VERSION ""

NS_ :

BS_:

BU_: Inverter SensorHub ECU AVA BMS

VAL_TABLE_ InverterCommandMode 0 "CAN Mode" 1 "VSM Mode" ;
VAL_TABLE_ InverterActiveDischargeState 0 "Discharge Disabled" 1 "Discharge Enabled, waiting" 2 "Performing Speed Check" 3 "Discharge Actively occurring" 4 "Discharge Completed" ;
VAL_TABLE_ SelfSensingAssistEnable 0 "Disabled" 1 "Enabled" ;
VAL_TABLE_ InverterRunMode 0 "Torque Mode" 1 "Speed Mode" ;
VAL_TABLE_ RelayState 0 "Relay 1 Status" 1 "Relay 2 Status" 2 "Relay 3 Status" 3 "Relay 4 Status" 4 "Relay 5 Status" 5 "Relay 6 Status" ;
VAL_TABLE_ InverterState 0 "Power On" 1 "Stop" 2 "Open Loop" 3 "Closed Loop" 4 "Wait" 5 "Internal" 6 "Internal" 7 "Internal" 8 "Idle Run" 9 "Idle Stop" 10 "Internal" 11 "Internal" 12 "Internal" ;
VAL_TABLE_ VSMState 0 "VSM Start" 1 "Pre-charge Init" 2 "Pre-charge Active" 3 "Pre-charge Complete" 4 "VSM Wait" 5 "VSM Ready" 6 "Motor Running" 7 "Blink Fault Code" 14 "Shutdown in Process" 15 "Recycle Power" ;
VAL_TABLE_ Write_Success 0 "Not Written" 1 "Success" ;
VAL_TABLE_ Read_Write 0 "Read" 1 "Write" ;

BO_ 288 GPSPos: 8 AVA
 SG_ longitude : 0|32@1- (1,0) [-180|180] "deg" Vector__XXX
 SG_ latitude : 32|32@1- (1,0) [-90|90] "deg" Vector__XXX

BO_ 289 GPSPosAuxiliary: 8 AVA
 SG_ GPSHorizAccuracy : 0|32@1- (1,0) [-3.4028234663852886e+38|3.4028234663852886e+38] "m" Vector__XXX
 SG_ GPSElevation : 32|32@1- (1,0) [-3.4028234663852886e+38|3.4028234663852886e+38] "m" Vector__XXX

BO_ 290 GPSSpeedDirection: 8 AVA
 SG_ GPSGroundSpeed : 0|32@1- (1,0) [-3.4028234663852886e+38|3.4028234663852886e+38] "m/s" Vector__XXX
 SG_ GPSHeading : 32|32@1- (1,0) [-3.4028234663852886e+38|3.4028234663852886e+38] "deg" Vector__XXX

BO_ 291 GPSStatus: 8 AVA
 SG_ GPSRTKStatus : 0|8@1+ (1,0) [0|255] "" Vector__XXX
 SG_ GPSNumSatellites : 8|8@1+ (1,0) [0|255] "" Vector__XXX

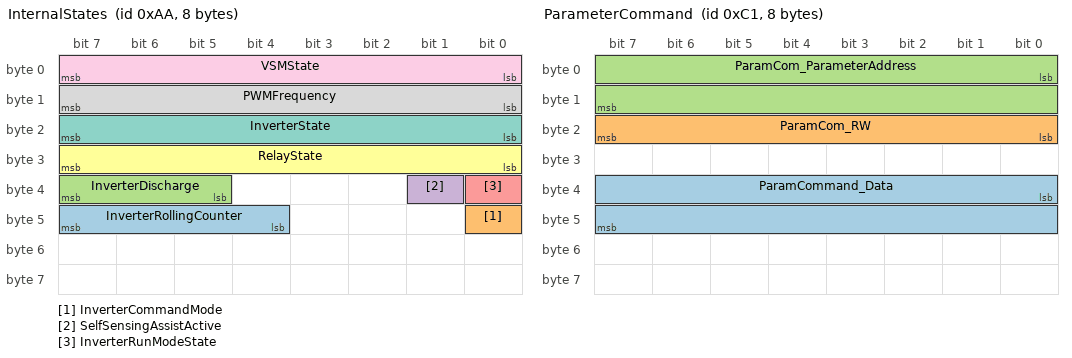
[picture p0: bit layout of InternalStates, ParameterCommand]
BO_ 170 InternalStates: 8 Inverter
 SG_ InverterRollingCounter : 44|4@1+ (1,0) [0|15] "" Vector__XXX
 SG_ InverterCommandMode : 40|1@1+ (1,0) [0|1] "" Vector__XXX
 SG_ InverterDischarge : 37|3@1+ (1,0) [0|4] "" Vector__XXX
 SG_ SelfSensingAssistActive : 33|1@1+ (1,0) [0|1] "" Vector__XXX
 SG_ InverterRunModeState : 32|1@1+ (1,0) [0|1] "" Vector__XXX
 SG_ RelayState : 24|8@1+ (1,0) [0|255] "" Vector__XXX
 SG_ InverterState : 16|8@1+ (1,0) [0|255] "" Vector__XXX
 SG_ PWMFrequency : 8|8@1+ (1,0) [0|255] "kHz" Vector__XXX
 SG_ VSMState : 0|8@1+ (1,0) [0|255] "" Vector__XXX

BO_ 193 ParameterCommand: 8 Inverter
 SG_ ParamCommand_Data : 32|16@1+ (1,0) [0|65535] "" Vector__XXX
 SG_ ParamCom_RW : 16|8@1- (1,0) [0|1] "" Vector__XXX
 SG_ ParamCom_ParameterAddress : 0|16@1+ (1,0) [0|65535] "" Vector__XXX

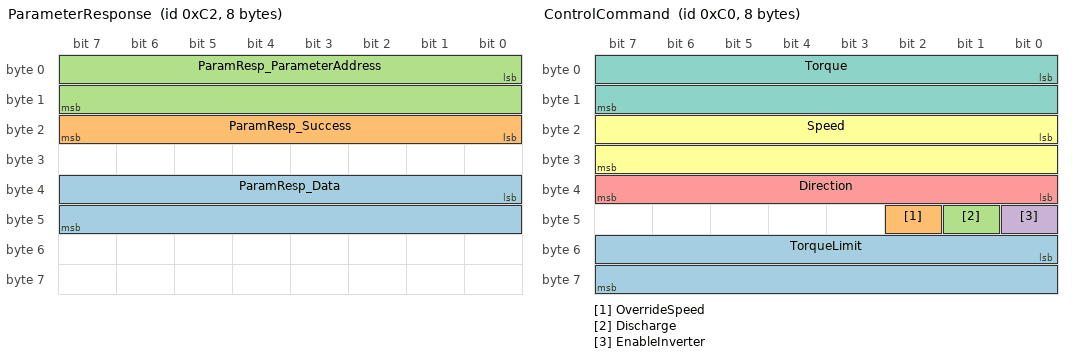
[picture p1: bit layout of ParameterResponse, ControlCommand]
BO_ 194 ParameterResponse: 8 Inverter
 SG_ ParamResp_Data : 32|16@1+ (1,0) [0|65535] "" Vector__XXX
 SG_ ParamResp_Success : 16|8@1+ (1,0) [0|1] "" Vector__XXX
 SG_ ParamResp_ParameterAddress : 0|16@1+ (1,0) [0|65535] "" Vector__XXX

BO_ 192 ControlCommand: 8 Inverter
 SG_ TorqueLimit : 48|16@1- (1,0) [-32768|32767] "0.1Nm" Vector__XXX
 SG_ OverrideSpeed : 42|1@1+ (1,0) [0|1] "" Vector__XXX
 SG_ Discharge : 41|1@1+ (1,0) [0|1] "" Vector__XXX
 SG_ EnableInverter : 40|1@1+ (1,0) [0|1] "" Vector__XXX
 SG_ Direction : 32|8@1+ (1,0) [0|1] "" Vector__XXX
 SG_ Speed : 16|16@1- (1,0) [-32768|32767] "RPM" Vector__XXX
 SG_ Torque : 0|16@1- (1,0) [-32768|32767] "0.1Nm" Vector__XXX

BO_ 177 TorqueCapability: 8 Inverter
 SG_ TorqueCapability : 0|16@1- (1,0) [-32768|32767] "0.1Nm" Vector__XXX

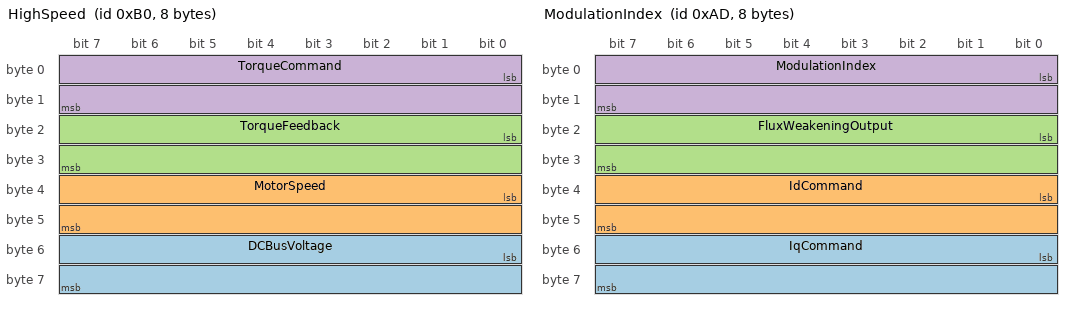
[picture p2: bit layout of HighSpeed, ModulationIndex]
BO_ 176 HighSpeed: 8 Inverter
 SG_ DCBusVoltage : 48|16@1- (0.1,0) [-3276.8|3276.7] "V" Vector__XXX
 SG_ MotorSpeed : 32|16@1- (1,0) [-32768|32767] "RPM" Vector__XXX
 SG_ TorqueFeedback : 16|16@1- (0.1,0) [-3276.8|3276.7] "Nm" Vector__XXX
 SG_ TorqueCommand : 0|16@1- (0.1,0) [-3276.8|3276.7] "Nm" Vector__XXX

BO_ 173 ModulationIndex: 8 Inverter
 SG_ IqCommand : 48|16@1- (1,0) [-32768|32767] "0.1V" Vector__XXX
 SG_ IdCommand : 32|16@1- (1,0) [-32768|32767] "0.1V" Vector__XXX
 SG_ FluxWeakeningOutput : 16|16@1- (1,0) [-32768|32767] "0.1V" Vector__XXX
 SG_ ModulationIndex : 0|16@1- (1,0) [-32768|32767] "0.01x" Vector__XXX

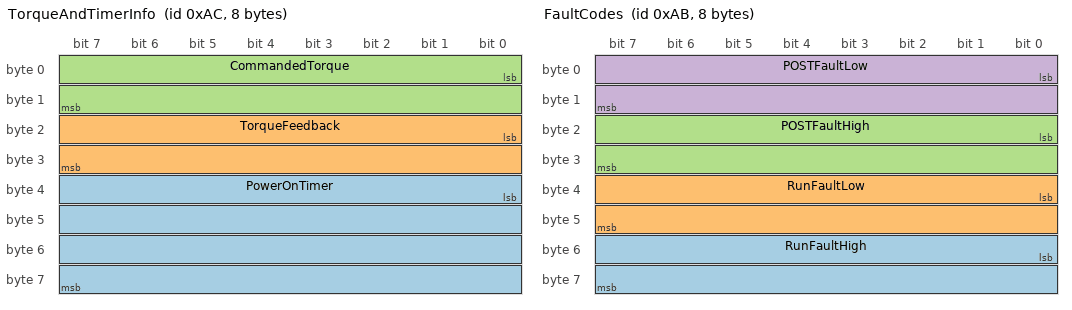
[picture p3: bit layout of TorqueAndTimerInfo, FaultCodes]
BO_ 172 TorqueAndTimerInfo: 8 Inverter
 SG_ PowerOnTimer : 32|32@1+ (1,0) [0|4294967295] "3ms" Vector__XXX
 SG_ TorqueFeedback : 16|16@1- (0.1,0) [-3276.8|3276.7] "Nm" Vector__XXX
 SG_ CommandedTorque : 0|16@1- (1,0) [-32768|32767] "0.1Nm" Vector__XXX

BO_ 171 FaultCodes: 8 Inverter
 SG_ RunFaultHigh : 48|16@1+ (1,0) [0|65535] "" Vector__XXX
 SG_ RunFaultLow : 32|16@1+ (1,0) [0|65535] "" Vector__XXX
 SG_ POSTFaultHigh : 16|16@1+ (1,0) [0|65535] "" Vector__XXX
 SG_ POSTFaultLow : 0|16@1+ (1,0) [0|65535] "" Vector__XXX

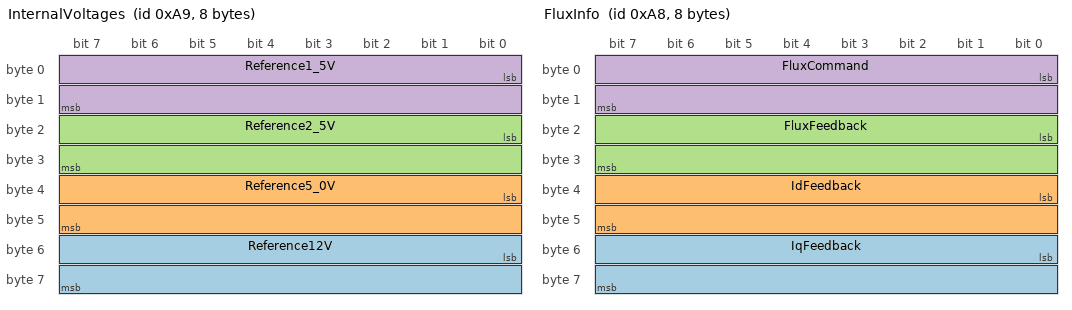
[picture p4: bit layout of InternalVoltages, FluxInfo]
BO_ 169 InternalVoltages: 8 Inverter
 SG_ Reference12V : 48|16@1- (0.01,0) [-327.68|327.67] "V" Vector__XXX
 SG_ Reference5_0V : 32|16@1- (1,0) [-32768|32767] "0.01V" Vector__XXX
 SG_ Reference2_5V : 16|16@1- (1,0) [-32768|32767] "0.01V" Vector__XXX
 SG_ Reference1_5V : 0|16@1- (1,0) [-32768|32767] "0.01V" Vector__XXX

BO_ 168 FluxInfo: 8 Inverter
 SG_ IqFeedback : 48|16@1- (1,0) [-32768|32767] "0.1A" Vector__XXX
 SG_ IdFeedback : 32|16@1- (1,0) [-32768|32767] "0.1A" Vector__XXX
 SG_ FluxFeedback : 16|16@1- (1,0) [-32768|32767] "mWb" Vector__XXX
 SG_ FluxCommand : 0|16@1- (1,0) [-32768|32767] "mWb" Vector__XXX

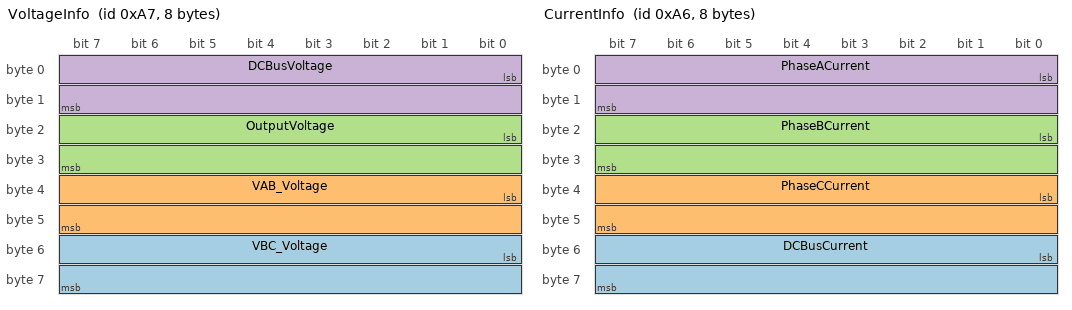
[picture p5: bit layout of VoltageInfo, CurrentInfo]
BO_ 167 VoltageInfo: 8 Inverter
 SG_ VBC_Voltage : 48|16@1- (1,0) [-32768|32767] "0.1V" Vector__XXX
 SG_ VAB_Voltage : 32|16@1- (1,0) [-32768|32767] "0.1V" Vector__XXX
 SG_ OutputVoltage : 16|16@1- (1,0) [-32768|32767] "0.1V" Vector__XXX
 SG_ DCBusVoltage : 0|16@1- (0.1,0) [-3276.8|3276.7] "V" Vector__XXX

BO_ 166 CurrentInfo: 8 Inverter
 SG_ DCBusCurrent : 48|16@1- (0.1,0) [-3276.8|3276.7] "A" Vector__XXX
 SG_ PhaseCCurrent : 32|16@1- (0.1,0) [-3276.8|3276.7] "A" Vector__XXX
 SG_ PhaseBCurrent : 16|16@1- (1,0) [-32768|32767] "0.1A" Vector__XXX
 SG_ PhaseACurrent : 0|16@1- (1,0) [-32768|32767] "0.1A" Vector__XXX

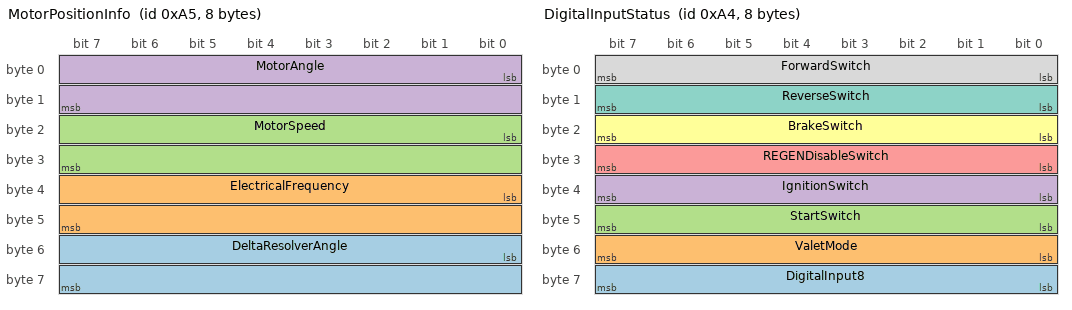
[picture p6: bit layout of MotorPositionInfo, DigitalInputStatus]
BO_ 165 MotorPositionInfo: 8 Inverter
 SG_ DeltaResolverAngle : 48|16@1- (1,0) [-32768|32767] "0.1deg" Vector__XXX
 SG_ ElectricalFrequency : 32|16@1- (1,0) [-32768|32767] "0.1Hz" Vector__XXX
 SG_ MotorSpeed : 16|16@1- (1,0) [-32768|32767] "RPM" Vector__XXX
 SG_ MotorAngle : 0|16@1- (1,0) [-32768|32767] "0.1deg" Vector__XXX

BO_ 164 DigitalInputStatus: 8 Inverter
 SG_ DigitalInput8 : 56|8@1+ (1,0) [0|1] "" Vector__XXX
 SG_ ValetMode : 48|8@1+ (1,0) [0|1] "" Vector__XXX
 SG_ StartSwitch : 40|8@1+ (1,0) [0|1] "" Vector__XXX
 SG_ IgnitionSwitch : 32|8@1+ (1,0) [0|1] "" Vector__XXX
 SG_ REGENDisableSwitch : 24|8@1+ (1,0) [0|1] "" Vector__XXX
 SG_ BrakeSwitch : 16|8@1+ (1,0) [0|1] "" Vector__XXX
 SG_ ReverseSwitch : 8|8@1+ (1,0) [0|1] "" Vector__XXX
 SG_ ForwardSwitch : 0|8@1+ (1,0) [0|1] "" Vector__XXX

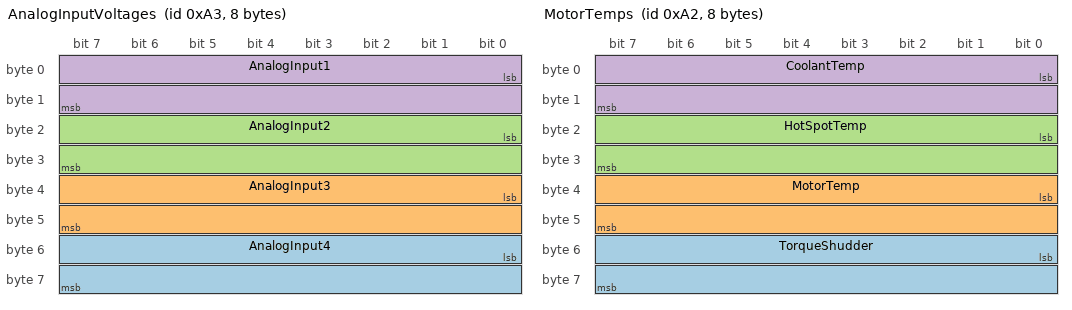
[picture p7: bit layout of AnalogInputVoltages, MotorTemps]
BO_ 163 AnalogInputVoltages: 8 Inverter
 SG_ AnalogInput4 : 48|16@1- (1,0) [-32768|32767] "" Vector__XXX
 SG_ AnalogInput3 : 32|16@1- (1,0) [-32768|32767] "" Vector__XXX
 SG_ AnalogInput2 : 16|16@1- (1,0) [-32768|32767] "" Vector__XXX
 SG_ AnalogInput1 : 0|16@1- (1,0) [-32768|32767] "" Vector__XXX

BO_ 162 MotorTemps: 8 Inverter
 SG_ TorqueShudder : 48|16@1- (1,0) [-32768|32767] "" Vector__XXX
 SG_ MotorTemp : 32|16@1- (1,0) [-32768|32767] "" Vector__XXX
 SG_ HotSpotTemp : 16|16@1- (1,0) [-32768|32767] "" Vector__XXX
 SG_ CoolantTemp : 0|16@1- (1,0) [-32768|32767] "" Vector__XXX

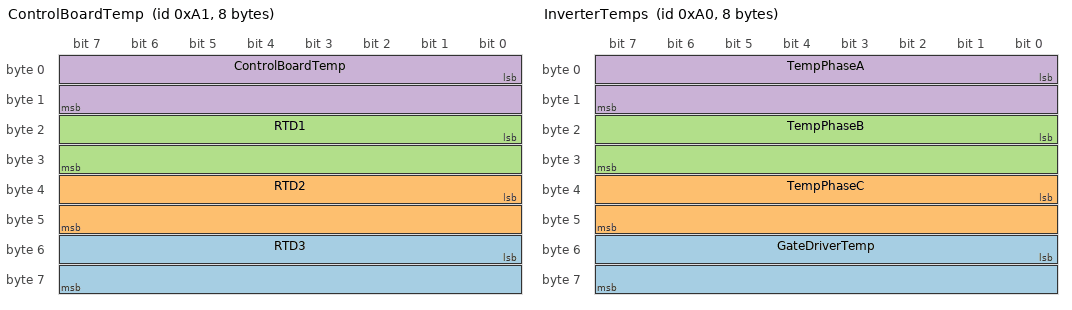
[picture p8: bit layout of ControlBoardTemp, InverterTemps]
BO_ 161 ControlBoardTemp: 8 Inverter
 SG_ RTD3 : 48|16@1- (1,0) [-32768|32767] "" Vector__XXX
 SG_ RTD2 : 32|16@1- (1,0) [-32768|32767] "" Vector__XXX
 SG_ RTD1 : 16|16@1- (1,0) [-32768|32767] "" Vector__XXX
 SG_ ControlBoardTemp : 0|16@1- (1,0) [-32768|32767] "" Vector__XXX

BO_ 160 InverterTemps: 8 Inverter
 SG_ GateDriverTemp : 48|16@1- (1,0) [-32768|32767] "" Vector__XXX
 SG_ TempPhaseC : 32|16@1- (1,0) [-32768|32767] "" Vector__XXX
 SG_ TempPhaseB : 16|16@1- (1,0) [-32768|32767] "" Vector__XXX
 SG_ TempPhaseA : 0|16@1- (1,0) [-32768|32767] "" Vector__XXX

BO_ 0 StartSwitch: 1 ECU
 SG_ StartSwitch : 0|8@1+ (1,0) [0|1] "" Vector__XXX

BO_ 1 Throttle1Position: 2 ECU
 SG_ Throttle1Position : 0|16@1+ (1,0) [0|65535] "" Vector__XXX

BO_ 2 Throttle2Position: 2 ECU
 SG_ Throttle2Position : 0|16@1+ (1,0) [0|65535] "" Vector__XXX

BO_ 3 BrakePressure: 2 ECU
 SG_ Brake : 0|16@1+ (1,0) [0|65535] "" Vector__XXX

BO_ 256 WheelSpeeds: 8 SensorHub
 SG_ WheelSpeedR : 0|32@1+ (1,0) [0|4294967295] "rpm" Vector__XXX
 SG_ WheelSpeedL : 32|32@1+ (1,0) [0|4294967295] "rpm" Vector__XXX

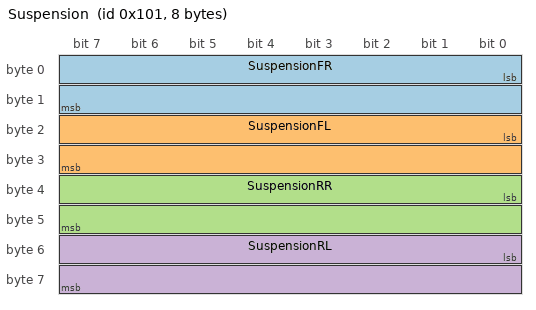
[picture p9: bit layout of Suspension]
BO_ 257 Suspension: 8 SensorHub
 SG_ SuspensionFR : 0|16@1+ (0.01,0) [0|655.35] "in" Vector__XXX
 SG_ SuspensionFL : 16|16@1+ (0.01,0) [0|655.35] "in" Vector__XXX
 SG_ SuspensionRR : 32|16@1+ (0.01,0) [0|655.35] "in" Vector__XXX
 SG_ SuspensionRL : 48|16@1+ (0.01,0) [0|655.35] "in" Vector__XXX

BO_ 258 SensHubPhysicalPos: 8 SensorHub
 SG_ SteeringAngle : 0|32@1- (1,0) [-3.4028234663852886e+38|3.4028234663852886e+38] "deg" Vector__XXX
 SG_ RideHeight : 32|32@1- (1,0) [-3.4028234663852886e+38|3.4028234663852886e+38] "in" Vector__XXX

BO_ 259 IMU_X: 8 SensorHub
 SG_ XAccel : 0|32@1- (1,0) [-3.4028234663852886e+38|3.4028234663852886e+38] "g" Vector__XXX
 SG_ XRotation : 32|32@1- (1,0) [-3.4028234663852886e+38|3.4028234663852886e+38] "deg/s" Vector__XXX

BO_ 260 IMU_Y: 8 SensorHub
 SG_ YAccel : 0|32@1- (1,0) [-3.4028234663852886e+38|3.4028234663852886e+38] "g" Vector__XXX
 SG_ YRotation : 32|32@1- (1,0) [-3.4028234663852886e+38|3.4028234663852886e+38] "deg/s" Vector__XXX

BO_ 261 IMU_Z: 8 SensorHub
 SG_ ZAccel : 0|32@1- (1,0) [-3.4028234663852886e+38|3.4028234663852886e+38] "g" Vector__XXX
 SG_ ZRotation : 32|32@1- (1,0) [-3.4028234663852886e+38|3.4028234663852886e+38] "deg/s" Vector__XXX

BO_ 262 CoolantInfo: 8 SensorHub
 SG_ CoolantFlow : 0|32@1- (1,0) [-3.4028234663852886e+38|3.4028234663852886e+38] "L/min" Vector__XXX
 SG_ CoolantPres : 32|32@1- (1,0) [-3.4028234663852886e+38|3.4028234663852886e+38] "bar" Vector__XXX

BO_ 263 LVSOC: 8 SensorHub
 SG_ VoltageCharge : 0|32@1- (1,0) [-3.4028234663852886e+38|3.4028234663852886e+38] "V" Vector__XXX

BO_ 264 BrakeTempFront: 8 SensorHub
 SG_ BrakeTempFR : 0|32@1- (1,0) [-3.4028234663852886e+38|3.4028234663852886e+38] "degC" Vector__XXX
 SG_ BrakeTempFL : 32|32@1- (1,0) [-3.4028234663852886e+38|3.4028234663852886e+38] "degC" Vector__XXX

BO_ 265 BrakeTempRear: 8 SensorHub
 SG_ BrakeTempRR : 0|32@1- (1,0) [-3.4028234663852886e+38|3.4028234663852886e+38] "degC" Vector__XXX
 SG_ BrakeTempRL : 32|32@1- (1,0) [-3.4028234663852886e+38|3.4028234663852886e+38] "degC" Vector__XXX

BO_ 266 CoolantTemp: 8 SensorHub
 SG_ CoolantTempA : 0|32@1- (1,0) [-3.4028234663852886e+38|3.4028234663852886e+38] "degC" Vector__XXX
 SG_ CoolantTempB : 32|32@1- (1,0) [-3.4028234663852886e+38|3.4028234663852886e+38] "degC" Vector__XXX

BO_ 267 ECUTemps: 8 SensorHub
 SG_ ECUBoardTemp : 0|32@1- (1,0) [-3.4028234663852886e+38|3.4028234663852886e+38] "degC" Vector__XXX
 SG_ ECUChipTemp : 32|32@1- (1,0) [-3.4028234663852886e+38|3.4028234663852886e+38] "degC" Vector__XXX

CM_ BU_ SensorHub "Transmits sensor board data on dataCAN (CAN2).";
CM_ BU_ AVA "Transmits GPS data on dataCAN (CAN2).";
CM_ SG_ 1 Throttle1Position "throttle 1 pos sensor";
CM_ SG_ 2 Throttle2Position "Throttle 2 pos sensor";
CM_ SG_ 3 Brake "Brake sensor";

BA_DEF_ "BusType" STRING ;
BA_DEF_ BO_ "GenMsgCycleTime" INT 0 65535;
BA_DEF_DEF_ "BusType" "CAN";
BA_DEF_DEF_ "GenMsgCycleTime" 0;

BA_ "GenMsgCycleTime" BO_ 256 5;
BA_ "GenMsgCycleTime" BO_ 257 5;
BA_ "GenMsgCycleTime" BO_ 258 5;
BA_ "GenMsgCycleTime" BO_ 259 5;
BA_ "GenMsgCycleTime" BO_ 260 5;
BA_ "GenMsgCycleTime" BO_ 261 5;
BA_ "GenMsgCycleTime" BO_ 262 10;
BA_ "GenMsgCycleTime" BO_ 263 100;
BA_ "GenMsgCycleTime" BO_ 264 250;
BA_ "GenMsgCycleTime" BO_ 265 250;
BA_ "GenMsgCycleTime" BO_ 266 250;
BA_ "GenMsgCycleTime" BO_ 267 500;
BA_ "GenMsgCycleTime" BO_ 288 100;
BA_ "GenMsgCycleTime" BO_ 289 100;
BA_ "GenMsgCycleTime" BO_ 290 100;
BA_ "GenMsgCycleTime" BO_ 291 100;

VAL_ 170 InverterCommandMode 0 "CAN Mode" 1 "VSM Mode" ;
VAL_ 170 InverterDischarge 0 "Discharge Disabled" 1 "Discharge Enabled, waiting" 2 "Performing Speed Check" 3 "Discharge Actively occurring" 4 "Discharge Completed" ;
VAL_ 170 SelfSensingAssistActive 0 "Disabled" 1 "Enabled" ;
VAL_ 170 InverterRunModeState 0 "Torque Mode" 1 "Speed Mode" ;
VAL_ 170 RelayState 0 "Relay 1 Status" 1 "Relay 2 Status" 2 "Relay 3 Status" 3 "Relay 4 Status" 4 "Relay 5 Status" 5 "Relay 6 Status" ;
VAL_ 170 InverterState 0 "Power On" 1 "Stop" 2 "Open Loop" 3 "Closed Loop" 4 "Wait" 5 "Internal" 6 "Internal" 7 "Internal" 8 "Idle Run" 9 "Idle Stop" 10 "Internal" 11 "Internal" 12 "Internal" ;
VAL_ 170 VSMState 0 "VSM Start" 1 "Pre-charge Init" 2 "Pre-charge Active" 3 "Pre-charge Complete" 4 "VSM Wait" 5 "VSM Ready" 6 "Motor Running" 7 "Blink Fault Code" 14 "Shutdown in Process" 15 "Recycle Power" ;
VAL_ 193 ParamCom_RW 0 "Read" 1 "Write" ;
VAL_ 194 ParamResp_Success 0 "Not Written" 1 "Success" ;

SIG_VALTYPE_ 258 SteeringAngle : 1;

SIG_VALTYPE_ 258 RideHeight : 1;

SIG_VALTYPE_ 259 XAccel : 1;

SIG_VALTYPE_ 259 XRotation : 1;

SIG_VALTYPE_ 260 YAccel : 1;

SIG_VALTYPE_ 260 YRotation : 1;

SIG_VALTYPE_ 261 ZAccel : 1;

SIG_VALTYPE_ 261 ZRotation : 1;

SIG_VALTYPE_ 262 CoolantFlow : 1;

SIG_VALTYPE_ 262 CoolantPres : 1;

SIG_VALTYPE_ 263 VoltageCharge : 1;

SIG_VALTYPE_ 264 BrakeTempFR : 1;

SIG_VALTYPE_ 264 BrakeTempFL : 1;

SIG_VALTYPE_ 265 BrakeTempRR : 1;

SIG_VALTYPE_ 265 BrakeTempRL : 1;

SIG_VALTYPE_ 266 CoolantTempA : 1;

SIG_VALTYPE_ 266 CoolantTempB : 1;

SIG_VALTYPE_ 267 ECUBoardTemp : 1;

SIG_VALTYPE_ 267 ECUChipTemp : 1;

SIG_VALTYPE_ 288 longitude : 1;

SIG_VALTYPE_ 288 latitude : 1;

SIG_VALTYPE_ 289 GPSHorizAccuracy : 1;

SIG_VALTYPE_ 289 GPSElevation : 1;

SIG_VALTYPE_ 290 GPSGroundSpeed : 1;

SIG_VALTYPE_ 290 GPSHeading : 1;
